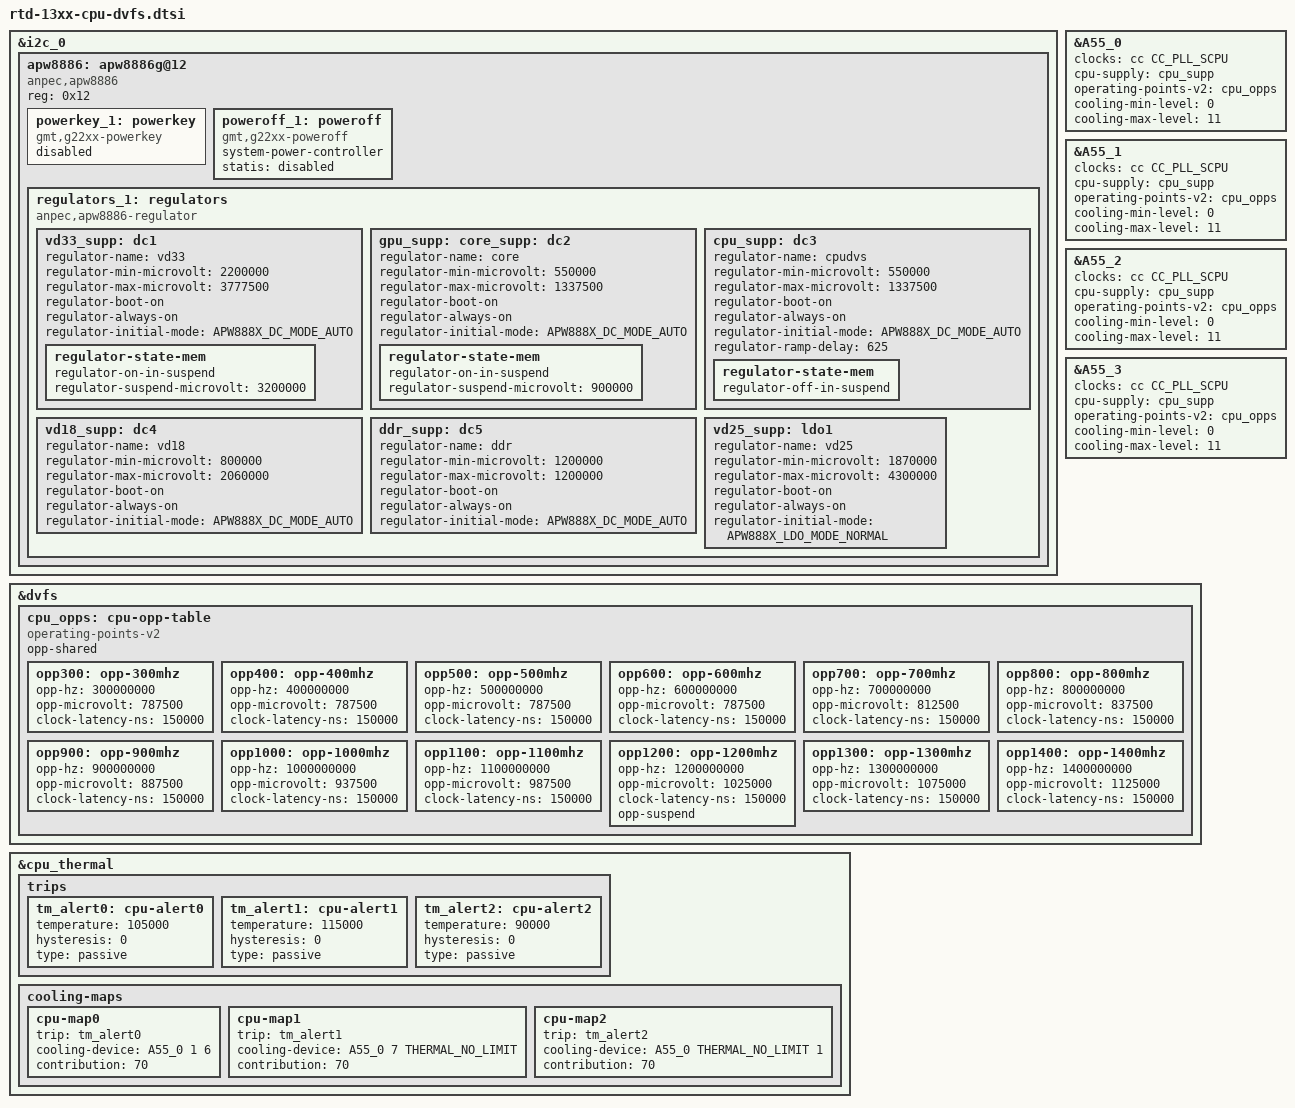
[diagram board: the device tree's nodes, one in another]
/*
 * RTD-13XX Generic CPU DVFS
 */
#include <dt-bindings/regulator/anpec,apw888x.h>
#include <dt-bindings/thermal/thermal.h>

/*
 * Frequnecy overview
 *
 *    CDEV                             CDEV  CDEV  CDEV
 *      ST  FREQUENCY  BOOST  SUSPEND  MAP0  MAP1  MAP2
 *       0       1400    V                          |
 *       1       1300                  -+-         -+-
 *       2       1200            V      |
 *       3       1100                   |
 *       4       1000                   |
 *       5        900                   |
 *       6        800                  -+-
 *       7        700                        -+-
 *       8        600                         |
 *       9        500                         |
 *      10        400                         |
 *      11        300                         |
 */

/* PMIC */
&i2c_0 {
	status = "okay";

	apw8886: apw8886g@12 {
		compatible = "anpec,apw8886";
		reg = <0x12>;

		status = "okay";

		powerkey_1: powerkey {
			compatible = "gmt,g22xx-powerkey";
			status = "disabled";
		};
		poweroff_1: poweroff {
			compatible = "gmt,g22xx-poweroff";
			system-power-controller;
			statis = "disabled";
		};
		regulators_1: regulators {
			compatible = "anpec,apw8886-regulator";
			status = "okay";
		};

	};
};

&apw8886 {
	regulators {
		vd33_supp: dc1 {
			regulator-name = "vd33";
			regulator-min-microvolt = <2200000>;
			regulator-max-microvolt = <3777500>;

			regulator-boot-on;
			regulator-always-on;
			regulator-initial-mode = <APW888X_DC_MODE_AUTO>;
			regulator-state-mem {
				regulator-on-in-suspend;
				regulator-suspend-microvolt = <3200000>;
			};
		};
		gpu_supp:
		core_supp: dc2 {
			regulator-name = "core";
			regulator-min-microvolt = <550000>;
			regulator-max-microvolt = <1337500>;

			regulator-boot-on;
			regulator-always-on;
			regulator-initial-mode = <APW888X_DC_MODE_AUTO>;
			regulator-state-mem {
				regulator-on-in-suspend;
				regulator-suspend-microvolt = <900000>;
			};
		};
		cpu_supp: dc3 {
			regulator-name = "cpudvs";
			regulator-min-microvolt = <550000>;
			regulator-max-microvolt = <1337500>;

			regulator-boot-on;
			regulator-always-on;
			regulator-initial-mode = <APW888X_DC_MODE_AUTO>;
			regulator-ramp-delay = <625>;
			regulator-state-mem {
				regulator-off-in-suspend;
			};
		};
		vd18_supp: dc4 {
			regulator-name = "vd18";
			regulator-min-microvolt = <800000>;
			regulator-max-microvolt = <2060000>;

			regulator-boot-on;
			regulator-always-on;
			regulator-initial-mode = <APW888X_DC_MODE_AUTO>;
		};
		ddr_supp: dc5 {
			regulator-name = "ddr";
			regulator-min-microvolt = <1200000>;
			regulator-max-microvolt = <1200000>;
			regulator-boot-on;
			regulator-always-on;
			regulator-initial-mode = <APW888X_DC_MODE_AUTO>;
		};
		vd25_supp: ldo1 {
			regulator-name = "vd25";
			regulator-min-microvolt = <1870000>;
			regulator-max-microvolt = <4300000>;

			regulator-boot-on;
			regulator-always-on;
			regulator-initial-mode = <APW888X_LDO_MODE_NORMAL>;
		};
	};
};

/* CPU nodes */
&A55_0 {
	clocks = <&cc CC_PLL_SCPU>;
	cpu-supply = <&cpu_supp>;
	operating-points-v2 = <&cpu_opps>;
	cooling-min-level = <0>;
	cooling-max-level = <11>;
	#cooling-cells = <2>;
};

&A55_1 {
	clocks = <&cc CC_PLL_SCPU>;
	cpu-supply = <&cpu_supp>;
	operating-points-v2 = <&cpu_opps>;
	cooling-min-level = <0>;
	cooling-max-level = <11>;
	#cooling-cells = <2>;
};

&A55_2 {
	clocks = <&cc CC_PLL_SCPU>;
	cpu-supply = <&cpu_supp>;
	operating-points-v2 = <&cpu_opps>;
	cooling-min-level = <0>;
	cooling-max-level = <11>;
	#cooling-cells = <2>;
};

&A55_3 {
	clocks = <&cc CC_PLL_SCPU>;
	cpu-supply = <&cpu_supp>;
	operating-points-v2 = <&cpu_opps>;
	cooling-min-level = <0>;
	cooling-max-level = <11>;
	#cooling-cells = <2>;
};

/* cpu opp table */
&dvfs {
	status = "okay";

	cpu_opps: cpu-opp-table {
		compatible = "operating-points-v2";
		opp-shared;
		opp300: opp-300mhz {
			opp-hz = /bits/ 64 <300000000>;
			opp-microvolt = <787500>;
			clock-latency-ns = <150000>;
			status = "okay";
		};
		opp400: opp-400mhz {
			opp-hz = /bits/ 64 <400000000>;
			opp-microvolt = <787500>;
			clock-latency-ns = <150000>;
			status = "okay";
		};
		opp500: opp-500mhz {
			opp-hz = /bits/ 64 <500000000>;
			opp-microvolt = <787500>;
			clock-latency-ns = <150000>;
			status = "okay";
		};
		opp600: opp-600mhz {
			opp-hz = /bits/ 64 <600000000>;
			opp-microvolt = <787500>;
			clock-latency-ns = <150000>;
			status = "okay";
		};
		opp700: opp-700mhz {
			opp-hz = /bits/ 64 <700000000>;
			opp-microvolt = <812500>;
			clock-latency-ns = <150000>;
			status = "okay";
		};
		opp800: opp-800mhz {
			opp-hz = /bits/ 64 <800000000>;
			opp-microvolt = <837500>;
			clock-latency-ns = <150000>;
			status = "okay";
		};
		opp900: opp-900mhz {
			opp-hz = /bits/ 64 <900000000>;
			opp-microvolt = <887500>;
			clock-latency-ns = <150000>;
			status = "okay";
		};
		opp1000: opp-1000mhz {
			opp-hz = /bits/ 64 <1000000000>;
			opp-microvolt = <937500>;
			clock-latency-ns = <150000>;
			status = "okay";
		};
		opp1100: opp-1100mhz {
			opp-hz = /bits/ 64 <1100000000>;
			opp-microvolt = <987500>;
			clock-latency-ns = <150000>;
			status = "okay";
		};
		opp1200: opp-1200mhz {
			opp-hz = /bits/ 64 <1200000000>;
			opp-microvolt = <1025000>;
			clock-latency-ns = <150000>;
			opp-suspend;
			status = "okay";
		};
		opp1300: opp-1300mhz {
			opp-hz = /bits/ 64 <1300000000>;
			opp-microvolt = <1075000>;
			clock-latency-ns = <150000>;
			status = "okay";
		};
		opp1400: opp-1400mhz {
			opp-hz = /bits/ 64 <1400000000>;
			opp-microvolt = <1125000>;
			clock-latency-ns = <150000>;
			status = "okay";
		};
	};
};

&cpu_thermal {
	trips {
		tm_alert0: cpu-alert0 {
			temperature = <105000>;
			hysteresis = <0>;
			type = "passive";
		};
		tm_alert1: cpu-alert1 {
			temperature = <115000>;
			hysteresis = <0>;
			type = "passive";
		};
		tm_alert2: cpu-alert2 {
			temperature = <90000>;
			hysteresis = <0>;
			type = "passive";
		};
	};
	cooling-maps {
		cpu-map0 {
			trip = <&tm_alert0>;
			cooling-device = <&A55_0 1 6>;
			contribution = <70>;
		};
		cpu-map1 {
			trip = <&tm_alert1>;
			cooling-device = <&A55_0 7 THERMAL_NO_LIMIT>;
			contribution = <70>;
		};
		cpu-map2 {
			trip = <&tm_alert2>;
			cooling-device = <&A55_0 THERMAL_NO_LIMIT 1>;
			contribution = <70>;
		};
	};
};
